# cslr_aif register map
Vendor: Texas Instruments
Peripheral module from a debugger description file.
Registers are 32-bit, access per field, reset 0x0 unless marked. A register's access mark holds for its fields unless they carry their own. Offsets are as the file gives them; lines under a group give offsets from that group; [hi:lo] are bit positions; {n}, {i} and the like mark numbered series; 'fields as' and 'values as' point back to an identical list; <NAME> marks a mode.

## AIF (part 1 of 5) — High-speed interface for BTS antenna data
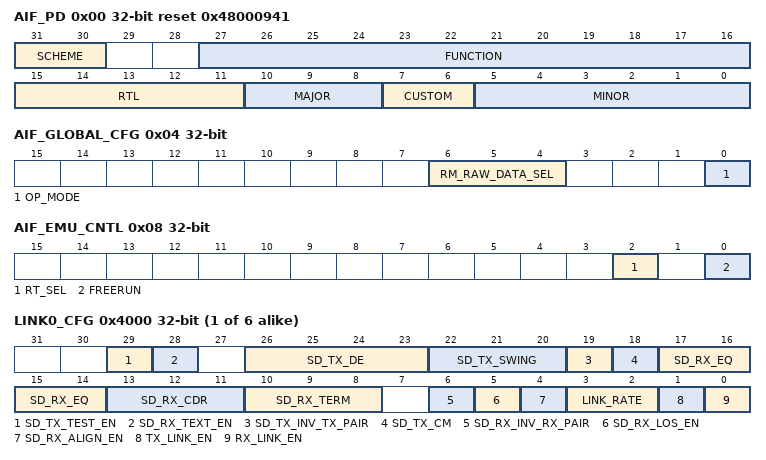
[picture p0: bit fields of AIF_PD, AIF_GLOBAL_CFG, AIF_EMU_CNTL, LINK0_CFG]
0x00 AIF_PD ro reset 0x48000941 — AI Periperal ID
  [31:30] SCHEME — Hard-coded to "01" to indicate current scheme
  [27:16] FUNCTION — Function code assigned to AI. Hard-coded to 0x800
  [15:11] RTL — RTL version code
  [10:8] MAJOR — Major revision (X) code
  [7:6] CUSTOM — Custom version code
  [5:0] MINOR — Minor revision (Y) code
0x04 AIF_GLOBAL_CFG — AI Global Configuration
  [6:4] RM_RAW_DATA_SEL rw — Select 1 of 6 links of raw (not gated) RX MAC output data used for data tracing feature.
  [0] OP_MODE rw — Select OBSAI '0' or CPRI '1' Operating mode. This bit must be set at device configuration and not changed.
0x08 AIF_EMU_CNTL — AI Emulation Control
  [2] RT_SEL rw — Source of emulation suspend signal
    0=EMUSUSP (Halt on emulation suspend); 1=EMUSUSP_RT (Halt on real-time emulation suspend)
  [0] FREERUN rw — Controls whether or not the AIF will respond to the emulation suspend signal, selected by RT_SEL
    0=HALT (AIF responds to emulation suspend signal); 1=FREE (AIF ignores the emulation suspend signal)
{0x4000+0x800*i} LINK{i}_CFG (i=0..5) — Link Configuration Register
  [29] SD_TX_TEST_EN rw — Enables test modes specified via TESTCFG for this transmitter (see SERDES spec)
  [28] SD_RX_TEXT_EN rw — Enables test modes specified via TESTCFG for this receiver (see SERDES spec)
  [26:23] SD_TX_DE rw — Selects one of 15 output de- emphasis settings from 4.76 to 71.42% (see SERDES spec)
  [22:20] SD_TX_SWING rw — Selects one of 8 output amplitude settings between 125 and 1250mVdfpp (see SERDES spec)
  [19] SD_TX_INV_TX_PAIR rw — Inverts polarity of TXPi and TXNi (see SERDES spec)
  [18] SD_TX_CM rw — Adjusts the common mode to suit the termination at the attached receiver (see SERDES spec)
  [17:14] SD_RX_EQ rw — Enables and configures the adaptive equalizer to compensate for loss in the transmission media (see SERDES spec)
  [13:11] SD_RX_CDR rw — Configures the clock/data recovery algorithm (see SERDES spec)
  [10:8] SD_RX_TERM rw — Selects input termination options suitable for variety of AC or DC coupled scenarios (see SERDES spec)
  [6] SD_RX_INV_RX_PAIR rw — Inverts polarity of RXPi and RXNi (see SERDES spec)
  [5] SD_RX_LOS_EN rw — Enable serdes loss of signal:
    0=DISABLED; 1=ENABLED
  [4] SD_RX_ALIGN_EN rw — Enables internal or external symbol alignment.
    0=DISABLED (Comma Alignment disabled); 1=ENABLED (Comma Alignment enabled)
  [3:2] LINK_RATE rw — Select both RX and TX line rate per link:
    0=4X; 1=2X; 2=1X
  [1] TX_LINK_EN rw — TX link enable: Affects SERDES, TX MAC, AG and PE.
    0=DISABLED; 1=ENABLED
  [0] RX_LINK_EN rw — RX link enable. Affects SERDES, RX MAC, CD and PD.
    0=DISABLED; 1=ENABLED
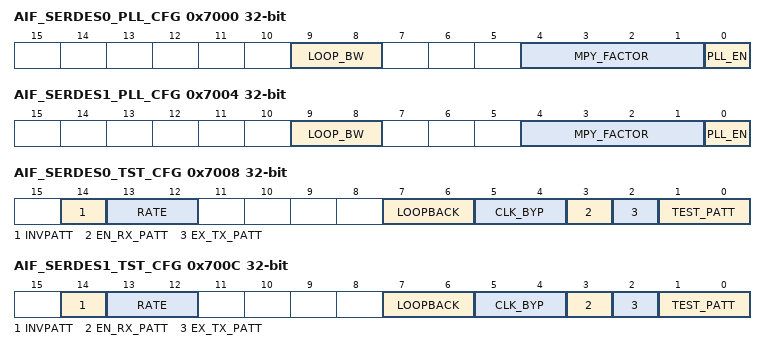
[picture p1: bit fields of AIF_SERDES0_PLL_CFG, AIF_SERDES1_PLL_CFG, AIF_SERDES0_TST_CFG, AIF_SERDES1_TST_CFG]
0x7000 AIF_SERDES0_PLL_CFG — AI Serdes 0 PLL Configuration
  [9:8] LOOP_BW rw — Specify loop bandwidth settings
  [4:1] MPY_FACTOR rw — Select PLL multiply factor (AI supports between 4 and 25)
  [0] PLL_EN rw — Enable PLL
    0=DISABLED; 1=ENABLED
0x7004 AIF_SERDES1_PLL_CFG — AI Serdes 1 PLL Configuration
  fields as AIF_SERDES0_PLL_CFG
0x7008 AIF_SERDES0_TST_CFG — AI Serdes 0 Test Configuration
  [14] INVPATT rw — Inverts polarity of pattern generator.
  [13:12] RATE rw — Selects rate for tx pattern generator.
  [7:6] LOOPBACK rw — Selects internal or bump/pad loopback
  [5:4] CLK_BYP rw — Facilitates bypassing of the PLL clock and bypassing of the recovered receive clock.
  [3] EN_RX_PATT rw — Enables generation of test patterns in the receiver
  [2] EX_TX_PATT rw — Enables generation of test patterns in the transmitter
  [1:0] TEST_PATT rw — Test Pattern selects one of two PRBS or two clock test patterns
0x700C AIF_SERDES1_TST_CFG — AI Serdes 1 Test Configuration
  fields as AIF_SERDES0_TST_CFG
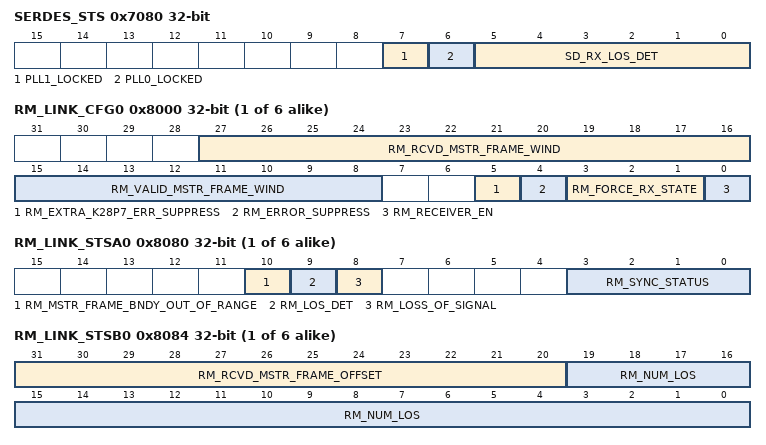
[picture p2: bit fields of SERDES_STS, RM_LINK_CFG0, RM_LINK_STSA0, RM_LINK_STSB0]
0x7080 SERDES_STS ro — SERDES Status Register
  [7] PLL1_LOCKED — Driven high when the PLL 1 is locked.
  [6] PLL0_LOCKED — Driven high when the PLL 0 is locked.
  [5:0] SD_RX_LOS_DET — Driven high when a loss of signal (electrical idle) condition is detected per link.
{0x8000+0x800*i} RM_LINK_CFG{i} (i=0..5) — Rx MAC Link Configuration Register
  [27:16] RM_RCVD_MSTR_FRAME_WIND rw — Defines the measurement window for received Master Frame Offset, given in the number of vbus_clk tics.
    0=DISABLE
  [15:8] RM_VALID_MSTR_FRAME_WIND rw — Defines the measurement window for valid Master Frame Offset, given in the number of vbus_clk tics. Related to the error: mstr_frame_bndry_out_of_range.
    0=DISABLE
  [5] RM_EXTRA_K28P7_ERR_SUPPRESS rw — Suppress error reporting of "extra" K28.7 characters detected in the data stream. RP3 requires that "messages be rejected when Master Frame boundary is detected outside the allowed window".
    0=ALLOW (Allow error reporting of extra K28.7 characters); 1=SUPPRESS (Suppress error reporting of extra K28.7 characters)
  [4] RM_ERROR_SUPPRESS rw — Suppress error reporting when the receiver state machine is not in state ST3.
    0=ALLOW (Allow RM error reporting when !ST3); 1=SUPPRESS (Suppress RM error reporting when !ST3)
  [3:1] RM_FORCE_RX_STATE rw — Force receiver state machine state: 0xx - not active, 100 - force ST0 state, 101 - force ST1 state, 110 - force ST2, 111 - force ST3 state.
  [0] RM_RECEIVER_EN rw — Enable '1' or disable '0' RX MAC.
    0=DISABLED; 1=ENABLED
{0x8004+0x800*i} RM_LINK_PI_OFFSET_CFG{i} (i=0..5) — Rx MAC Link Pi Offset Configuration Register
  [19:0] RM_PI_OFFSET rw — A 2's compliment number specifying the delay from Frame Sync to the expected Master Frame / Hyper Frame boundary (OBSAI RP3: K28.7 or CPRI: K28.5 AND HFN = 149) within ~65 ns (about 5, 1x link byte clocks) and given in the number of vbus_clk tics.
{0x8008+0x800*i} RM_LINK_LOS_THOLD_CFG{i} (i=0..5) — Rx MAC Link LoS Threshold Configuration Register
  [19:0] RM_LOS_DET_THOLD rw — Sets 8b10b los detect threshold values in number of Line Code Violations received. Writing to this location will automatically clear the rm_num_los counter and rm_los_det status bit.
{0x8080+0x800*i} RM_LINK_STSA{i} ro (i=0..5) — RX MAC Link Status Register A
  [10] RM_MSTR_FRAME_BNDY_OUT_OF_RANGE — This error is indicated when received Master Frame is detected outside the programmable window valid_mstr_frame_wind. This error will not be reported if an "extra" K28.7 character is detected AND rm_extra_k28p7_err_suppress = 1.
  [9] RM_LOS_DET — Detectes when rm_num_los counter has reached the programmable rm_los_det_thold limit.
    0=NOT_DETECTED; 1=DETECTED
  [8] RM_LOSS_OF_SIGNAL — Active when rx state machine is in ST0 state, inactive otherwise.
  [3:0] RM_SYNC_STATUS — Indicates the current status of the rx state machine. ST0 = '1000', ST1 = '0100', ST2 = '0010', ST3 = '0001'
{0x8084+0x800*i} RM_LINK_STSB{i} ro (i=0..5) — RX MAC Link Status Register B
  [31:20] RM_RCVD_MSTR_FRAME_OFFSET — Reperesents the time in vbus_clk tics from after pi_offset that the frame boundary was received. This value will saturate at either the programmed rm_rcvd_mstr_frame_wind threshold or the max value of 4095. This measurement is conducted once per frame.
  [19:0] RM_NUM_LOS — This error is indicated when received Master Frame is detected outside the programmable window valid_mstr_frame_wind. This error will not be reported if an "extra" K28.7 character is detected AND rm_extra_k28p7_err_suppress = 1.
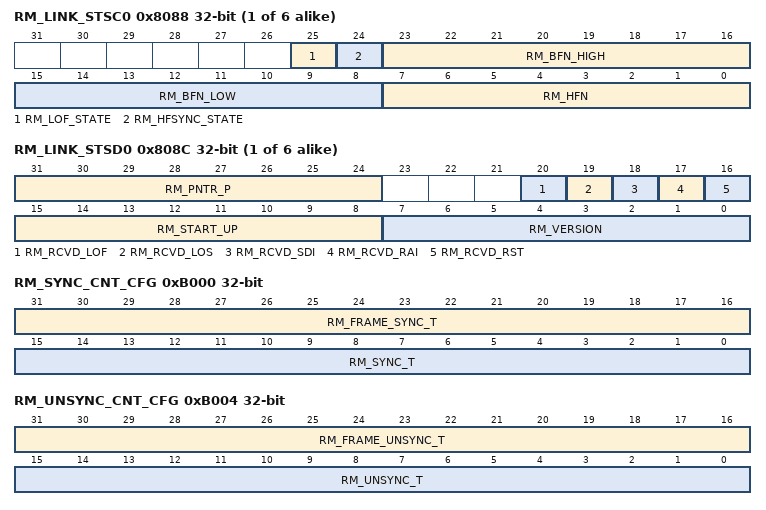
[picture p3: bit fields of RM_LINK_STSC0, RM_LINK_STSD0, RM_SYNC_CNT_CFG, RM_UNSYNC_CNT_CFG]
{0x8088+0x800*i} RM_LINK_STSC{i} (i=0..5) — RX MAC Link Status Register C
  [25] RM_LOF_STATE rw — Active high status indicates Loss Of Frame when the receiver FSM is in state ST0 or ST1.
  [24] RM_HFSYNC_STATE rw — Active high status indicates when the receiver FSM is in the HFSYNC state ST3.
  [23:16] RM_BFN_HIGH ro — Received Node B Frame number high byte (Z.130.0)
  [15:8] RM_BFN_LOW ro — Received Node B Frame number low byte (Z.128.0)
  [7:0] RM_HFN ro — Received Hyperframe number (Z.64.0)
{0x808C+0x800*i} RM_LINK_STSD{i} ro (i=0..5) — RX MAC Link Status Register D
  [31:24] RM_PNTR_P — Received Pointer P
  [20] RM_RCVD_LOF — Received lof (Z.130.0, b4)
  [19] RM_RCVD_LOS — Received los (Z.130.0, b3)
  [18] RM_RCVD_SDI — Received sdi (Z.130.0, b2)
  [17] RM_RCVD_RAI — Received rai (Z.130.0, b1)
  [16] RM_RCVD_RST — Received reset (Z.130.0, b0)
  [15:8] RM_START_UP — Received start-up information (Z.66.0)
  [7:0] RM_VERSION — Received protocol version (Z.2.0)
0xB000 RM_SYNC_CNT_CFG rw — Rx MAC Sync Count Configuration Register
  [31:16] RM_FRAME_SYNC_T — Threshold value for consecutive valid message groups which result in state ST3
  [15:0] RM_SYNC_T — Threshold value for consecutive valid blocks of bytes which result in state ST1.
0xB004 RM_UNSYNC_CNT_CFG rw — Rx MAC Unsync Count Configuration Register
  [31:16] RM_FRAME_UNSYNC_T — Threshold value for consecutive invalid message groups which result in state ST1.
  [15:0] RM_UNSYNC_T — Threshold value for consecutive invalid blocks of bytes which result in state ST0.
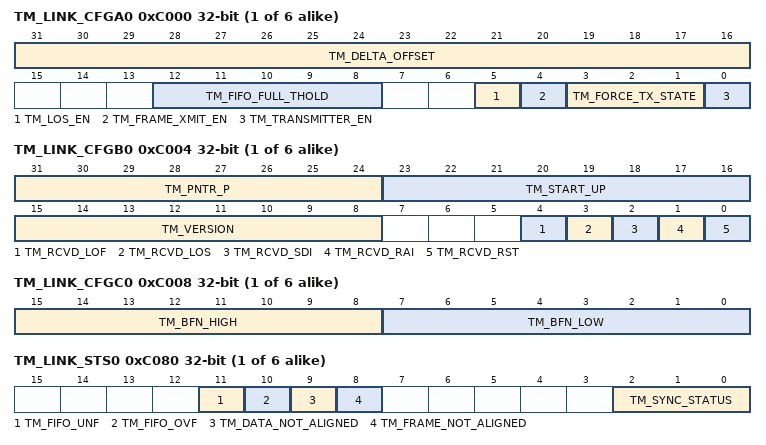
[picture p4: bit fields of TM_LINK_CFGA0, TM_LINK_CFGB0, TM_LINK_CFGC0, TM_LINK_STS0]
{0xC000+0x800*i} TM_LINK_CFGA{i} (i=0..5) — Tx MAC Link Configuration RegisterA
  [31:16] TM_DELTA_OFFSET rw — A 2's compliment number specifying the delay from Frame Sync to start of Master Frame in 1x link byte-clock ticks (13ns) increments.
  [12:8] TM_FIFO_FULL_THOLD rw — Sets the threshold for the full indication flag for the TX MAC FIFO.
  [5] TM_LOS_EN rw — Enable impact of the rm_loss_of_signal to the transmitter state machine:
    0=DISABLED; 1=ENABLED
  [4] TM_FRAME_XMIT_EN rw — Enable allowing the TX FSM from entering state ST2. Thisbit will have no effect if the state machine is already in state ST2.
    0=DISABLED; 1=ENABLED
  [3:1] TM_FORCE_TX_STATE rw — Force transmitter state machine state:
    0=NOT_ACTIVE0; 4=FORCE_ST0; 5=FORCE_ST1; 6=FORCE_ST2
  [0] TM_TRANSMITTER_EN rw — TX MAC enable:
    0=DISABLED; 1=ENABLED
{0xC004+0x800*i} TM_LINK_CFGB{i} rw (i=0..5) — Tx MAC Link Configuration Register B
  [31:24] TM_PNTR_P — Transmit Pointer P
  [23:16] TM_START_UP — Transmit start-up information (Z.66.0)
  [15:8] TM_VERSION — Transmit protocol version (Z.2.0)
  [4] TM_RCVD_LOF — Transmit lof (Z.130.0, b4)
  [3] TM_RCVD_LOS — Transmit los (Z.130.0, b3)
  [2] TM_RCVD_SDI — Transmit sdi (Z.130.0, b2)
  [1] TM_RCVD_RAI — Transmit rai (Z.130.0, b1)
  [0] TM_RCVD_RST — Transmit reset (Z.130.0, b0)
{0xC008+0x800*i} TM_LINK_CFGC{i} (i=0..5) — Tx MAC Link Configuration Register C
  [15:8] TM_BFN_HIGH rw — Transmit Node B Frame number high byte (Z.130.0) - loads u_cntr high byte
  [7:0] TM_BFN_LOW rw — Transmit Node B Frame number low byte (Z.128.0) - loads u_cntr low byte
{0xC080+0x800*i} TM_LINK_STS{i} ro (i=0..5) — TX MAC Link Status Register
  [11] TM_FIFO_UNF — TX MAC FIFO Underflow flag
  [10] TM_FIFO_OVF — TX MAC FIFO Overflow flag
  [9] TM_DATA_NOT_ALIGNED — This error is indicated when data to be transmitted is detected as not aligned with Master Frame + delta_offset (i.e. Frame boundary to be transmitted is not aligned with frame boundary received internally)
  [8] TM_FRAME_NOT_ALIGNED — This error is indicated when the frame strobe from the Frame Sync Module is not aligned with Master Frame + delta_offset.
  [2:0] TM_SYNC_STATUS — Indicates the current status of the tx state machine.
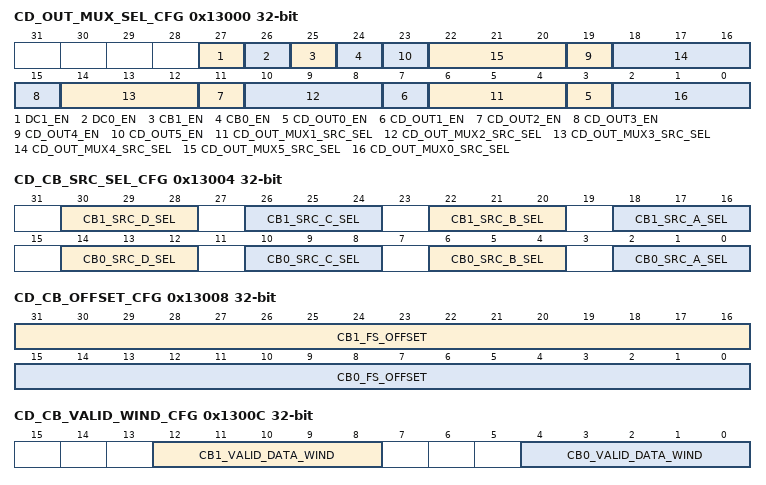
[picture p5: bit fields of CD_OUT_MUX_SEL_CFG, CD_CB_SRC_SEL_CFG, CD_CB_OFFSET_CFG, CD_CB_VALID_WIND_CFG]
0x13000 CD_OUT_MUX_SEL_CFG — Combiner - Decombiner Output Mux Select Config Register 0
  [27] DC1_EN rw — Decombiner 1 enable
    0=DISABLE; 1=ENABLE
  [26] DC0_EN rw — Decombiner 0 enable
    0=DISABLE; 1=ENABLE
  [25] CB1_EN rw — Combiner 1 enable
    0=DISABLE; 1=ENABLE
  [24] CB0_EN rw — Combiner 0 enable
    0=DISABLE; 1=ENABLE
  [4n+3] CD_OUT{n}_EN rw (n=0..5) — CD output {n} enable: Disable = 0, Enable =1 output link {n} of the Combiner / Decombiner.
    0=DISABLE; 1=ENABLE
  [4n+2:4n] CD_OUT_MUX{n}_SRC_SEL rw (n=1..5) — Select source of link {n} output
    {v}=LINK_{v} (v=0..5); 6=CB_0; 7=CB_1
  [2:0] CD_OUT_MUX0_SRC_SEL rw — Select source of link 0 output:
    {v}=LINK_{v} (v=0..5); 6=CB_0; 7=CB_1
0x13004 CD_CB_SRC_SEL_CFG — Combiner Source Select Config Register
  [all] fields
    {v}=LINK_{v} (v=0..5)
  [30:28] CB1_SRC_D_SEL rw — Combiner 1 input source link select table entry 'd'
  [26:24] CB1_SRC_C_SEL rw — Combiner 1 input source link select table entry 'c'
  [22:20] CB1_SRC_B_SEL rw — Combiner 1 input source link select table entry 'b'
  [18:16] CB1_SRC_A_SEL rw — Combiner 1 input source link select table entry 'a'
  [14:12] CB0_SRC_D_SEL rw — Combiner 0 input source link select table entry 'd'
  [10:8] CB0_SRC_C_SEL rw — Combiner 0 input source link select table entry 'c'
  [6:4] CB0_SRC_B_SEL rw — Combiner 0 input source link select table entry 'b'
  [2:0] CB0_SRC_A_SEL rw — Combiner 0 input source link select table entry 'a'
0x13008 CD_CB_OFFSET_CFG rw — Combiner Alignment Offset Config Register
  [31:16] CB1_FS_OFFSET — Combiner 1 offset from frame sync. Similar to RX MAC pi_offset. This value is used to check input link frame alignment.
  [15:0] CB0_FS_OFFSET — Combiner 0 offset from frame sync. Similar to RX MAC pi_offset. This value is used to check input link frame alignment.
0x1300C CD_CB_VALID_WIND_CFG — Combiner Valid Window Config Register
  [12:8] CB1_VALID_DATA_WIND rw — Combiner 1 valid data window for Master Frame Offset in vbus clock ticks
  [4:0] CB0_VALID_DATA_WIND rw — Combiner 0 valid data window for Master Frame Offset in vbus clock ticks
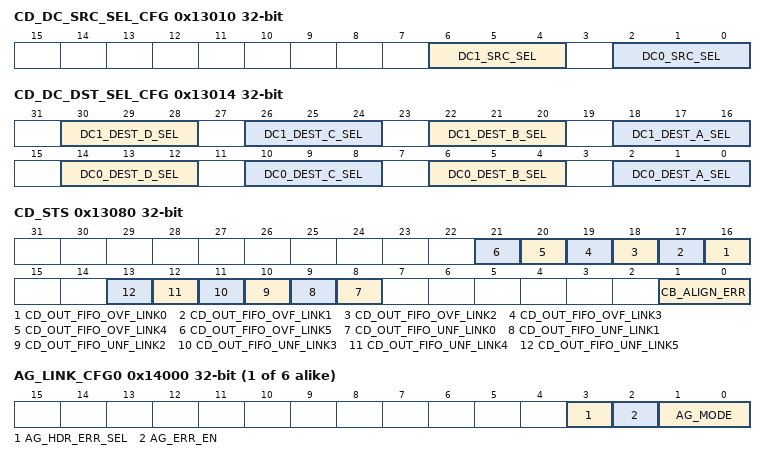
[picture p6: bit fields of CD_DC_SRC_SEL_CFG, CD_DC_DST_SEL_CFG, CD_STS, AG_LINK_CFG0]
0x13010 CD_DC_SRC_SEL_CFG — Decombiner Source Select Config Register
  [6:4] DC1_SRC_SEL rw — Decombiner 1 source
    {v}=LINK_{v} (v=0..5)
  [2:0] DC0_SRC_SEL rw — Decombiner 0 source
    {v}=LINK_{v} (v=0..5)
0x13014 CD_DC_DST_SEL_CFG — Decombiner Destination Select Config Register
  [all] fields
    {v}=LINK_{v} (v=0..5)
  [30:28] DC1_DEST_D_SEL rw — Decombiner 1 output destination link select table entry 'd'
  [26:24] DC1_DEST_C_SEL rw — Decombiner 1 output destination link select table entry 'c'
  [22:20] DC1_DEST_B_SEL rw — Decombiner 1 output destination link select table entry 'b'
  [18:16] DC1_DEST_A_SEL rw — Decombiner 1 output destination link select table entry 'a'
  [14:12] DC0_DEST_D_SEL rw — Decombiner 0 output destination link select table entry 'd'
  [10:8] DC0_DEST_C_SEL rw — Decombiner 0 output destination link select table entry 'c'
  [6:4] DC0_DEST_B_SEL rw — Decombiner 0 output destination link select table entry 'b'
  [2:0] DC0_DEST_A_SEL rw — Decombiner 0 output destination link select table entry 'a'
0x13080 CD_STS ro — Combiner - Decombiner Status Register
  [n+16] CD_OUT_FIFO_OVF_LINK{n} (n=0..5) — Active high. CD output FIFO overflow flag per link
  [n+8] CD_OUT_FIFO_UNF_LINK{n} (n=0..5) — Active high. CD output FIFO underflow flag per link
  [1:0] CB_ALIGN_ERR — Active high. Indicates frame alignment error for each of the two combiners.
{0x14000+0x800*i} AG_LINK_CFG{i} (i=0..5) — Aggregator Link Configuration Register
  [3] AG_HDR_ERR_SEL rw — Controls the data source selected by aggregator when there is an OBSAI header mismatch and the PE is requesting aggregation
  [2] AG_ERR_EN rw — Aggregator error checking enable: 0 = aggregator error checking disabled, 1 = aggregator error checking enabled.
  [1:0] AG_MODE rw — Select aggregator mode: 00 = Not enabled (no data sent to the TX MAC), 01 = Pass thru from Combiner only, 10 = Insertion from the Protocol Encoder only, 11 = All aggregation functions enabled.
{0x14004+0x800*i} AG_LINK_STS{i} ro (i=0..5) — Aggregator Link Error Status Register
  [15:0] AG_AXC_SUM_OVF — Summation overflow per AxC.
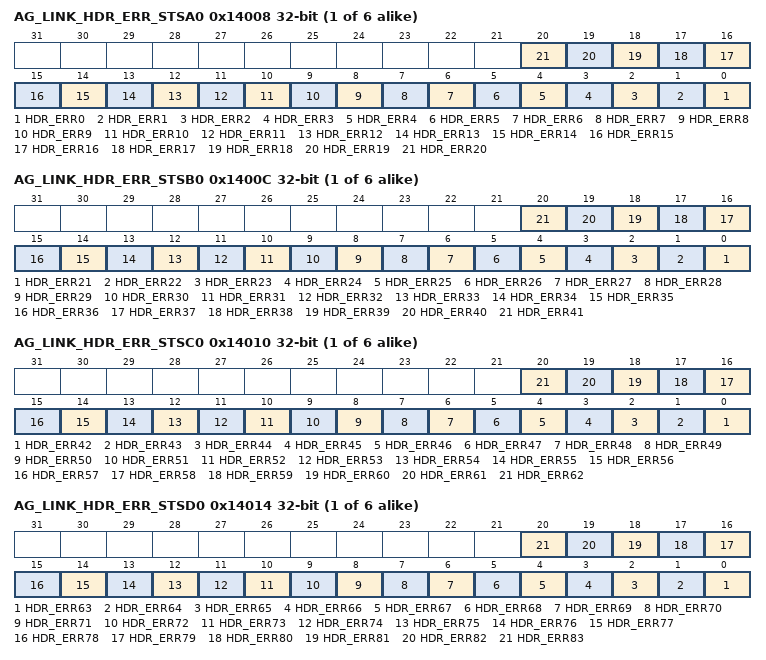
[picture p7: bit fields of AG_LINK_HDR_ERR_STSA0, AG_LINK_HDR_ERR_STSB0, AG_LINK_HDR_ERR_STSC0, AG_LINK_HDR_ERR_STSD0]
{0x14008+0x800*i} AG_LINK_HDR_ERR_STSA{i} ro (i=0..5) — Aggregator Link Header Error Status Register A
  [all] fields
    0=NO_ERR; 1=ERR
  [n] HDR_ERR{n} (n=0..20) — Aggregator header error for slot {n}
{0x1400C+0x800*i} AG_LINK_HDR_ERR_STSB{i} ro (i=0..5) — Aggregator Link Header Error Status Register B
  [all] fields
    0=NO_ERR; 1=ERR
  [n-21] HDR_ERR{n} (n=21..41) — Aggregator header error for slot {n}
{0x14010+0x800*i} AG_LINK_HDR_ERR_STSC{i} ro (i=0..5) — Aggregator Link Header Error Status Register C
  [all] fields
    0=NO_ERR; 1=ERR
  [n-42] HDR_ERR{n} (n=42..62) — Aggregator header error for slot {n}
{0x14014+0x800*i} AG_LINK_HDR_ERR_STSD{i} ro (i=0..5) — Aggregator Link Header Error Status Register D
  [all] fields
    0=NO_ERR; 1=ERR
  [n-63] HDR_ERR{n} (n=63..83) — Aggregator header error for slot {n}
{0x18000+0x800*i} CI_LINK_CFG{i} (i=0..5) — CPRI Link Input Data Format Converter Configuration Registers
  [1:0] CI_DATA_FMT rw — CPRI data format:
    0=UL_PIC_7BIT; 1=UL_PIC_8BIT; 2=DL_GEN_15BIT; 3=DL_GEN_16BIT
{0x1C000+0x800*i} CO_LINK_CFG{i} (i=0..5) — CPRI Link Output Data Format Converter Configuration Registers
  [1:0] CO_DATA_FMT rw — CPRI data format:
    0=UL_PIC_7BIT; 1=UL_PIC_8BIT; 2=DL_GEN_15BIT; 3=DL_GEN_16BIT
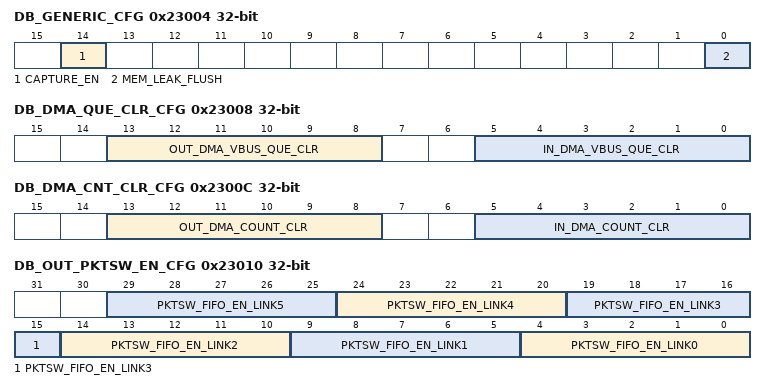
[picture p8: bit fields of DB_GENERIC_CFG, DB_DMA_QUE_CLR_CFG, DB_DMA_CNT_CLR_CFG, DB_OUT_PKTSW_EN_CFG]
0x23004 DB_GENERIC_CFG — Data Buffer Configuration Register
  [14] CAPTURE_EN rw — Enables "Logic Analyzer" capture
  [0] MEM_LEAK_FLUSH rw — Flushes all outbound pktsw fifo's if a memory leak is detected
0x23008 DB_DMA_QUE_CLR_CFG — Data Buffer DMA Depth Clear Register
  [13:8] OUT_DMA_VBUS_QUE_CLR wo — Bits [5:0]: Bit mapped per link, clears the Outbound DMA VBUS Queue counters
  [5:0] IN_DMA_VBUS_QUE_CLR wo — Bits [5:0]: Bit mapped per link, clears the Inbound DMA VBUS Queue counters
0x2300C DB_DMA_CNT_CLR_CFG — Data Buffer DMA Count Clear Register
  [13:8] OUT_DMA_COUNT_CLR wo — Bits [5:0]: Bit mapped per link, clears the Outbound DMA "Depth" counters
  [5:0] IN_DMA_COUNT_CLR wo — Bits [5:0]: Bit mapped per link, clears the Inbound DMA "Depth" counters
0x23010 DB_OUT_PKTSW_EN_CFG — Data Buffer Outbound Packet Switched FIFO Enable Register
  [5n+4:5n] PKTSW_FIFO_EN_LINK{n} rw (n=0..5) — Bit mapped per Channel, Enables Packet Switched Outbound FIFOs
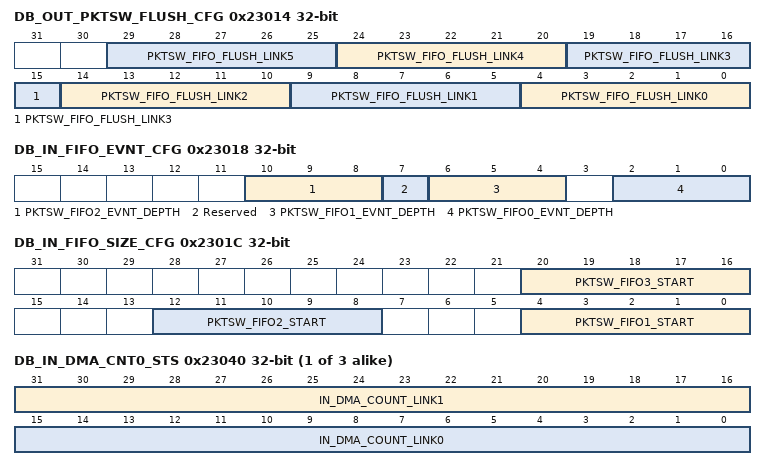
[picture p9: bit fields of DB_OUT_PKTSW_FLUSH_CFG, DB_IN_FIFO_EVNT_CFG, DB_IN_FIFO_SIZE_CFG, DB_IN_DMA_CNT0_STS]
0x23014 DB_OUT_PKTSW_FLUSH_CFG — Data Buffer Inbound Packet Switched FIFO Flush Register
  [5n+4:5n] PKTSW_FIFO_FLUSH_LINK{n} wo (n=0..5) — Bit mapped per Channel, Enables Packet Switched Outbound FIFOs
0x23018 DB_IN_FIFO_EVNT_CFG access not given — Data Buffer Inbound Packet Switched FIFO Flush Register
  [10:8] PKTSW_FIFO2_EVNT_DEPTH rw — Inbound Packet Swtiched FIFO #2, programmable depth of system event
    0=DEPTH_01 (Queue depth of 1); 1=DEPTH_02 (Queue depth of 2); 2=DEPTH_04 (Queue depth of 4); 3=DEPTH_08 (Queue depth of 8); 4=DEPTH_16 (Queue depth of 16); 5=DEPTH_32 (Queue depth of 32)
  [7] Reserved — (access N)
  [6:4] PKTSW_FIFO1_EVNT_DEPTH rw — Inbound Packet Swtiched FIFO #1, programmable depth of system event
    values as PKTSW_FIFO2_EVNT_DEPTH
  [2:0] PKTSW_FIFO0_EVNT_DEPTH rw — Inbound Packet Swtiched FIFO #0, programmable depth of system event
    values as PKTSW_FIFO2_EVNT_DEPTH
0x2301C DB_IN_FIFO_SIZE_CFG — Data Buffer Inbound Packet Switched FIFO Depth Register
  [20:16] PKTSW_FIFO3_START rw — Inbound Packet Swtiched FIFO #3 start
  [12:8] PKTSW_FIFO2_START rw — Inbound Packet Swtiched FIFO #2 start
  [4:0] PKTSW_FIFO1_START rw — Inbound Packet Swtiched FIFO #1 start
{0x23040+4i} DB_IN_DMA_CNT{i}_STS ro (i=0..2) — Data Buffer Inbound DMA Count {i} Register
  [31:16] IN_DMA_COUNT_LINK{2i+1} — DMA Inbound Done Register Occurances for Link {2i+1}
  [15:0] IN_DMA_COUNT_LINK{2i} — DMA Inbound Done Register Occurances for Link {2i}
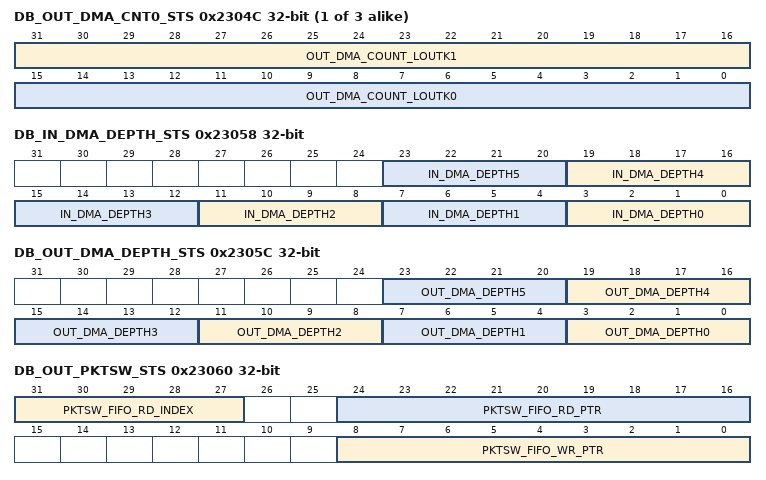
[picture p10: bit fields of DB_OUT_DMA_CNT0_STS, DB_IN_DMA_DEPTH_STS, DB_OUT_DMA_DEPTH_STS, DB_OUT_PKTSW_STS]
{0x2304C+4i} DB_OUT_DMA_CNT{i}_STS ro (i=0..2) — Data Buffer Outbound DMA Count {i} Register
  [31:16] OUT_DMA_COUNT_LOUTK{2i+1} — DMA Outbound Done Register Occurances for Link {2i+1}
  [15:0] OUT_DMA_COUNT_LOUTK{2i} — DMA Outbound Done Register Occurances for Link {2i}
0x23058 DB_IN_DMA_DEPTH_STS — Data Buffer Inbound DMA Burst Available Register
  [4n+3:4n] IN_DMA_DEPTH{n} rw (n=0..5) — Number of DMA bursts written into DB by PD for Link {n}
0x2305C DB_OUT_DMA_DEPTH_STS — Data Buffer Outbound DMA Burst Available Register
  [4n+3:4n] OUT_DMA_DEPTH{n} rw (n=0..5) — Number of DMA bursts written into DB by PE for Link {n}
0x23060 DB_OUT_PKTSW_STS ro — Data Buffer Outbound Packet Switched FIFO status Register
  [31:27] PKTSW_FIFO_RD_INDEX — Fifo Index 0-to-29 indicating which of 30 FIFOs has the lowest, non-read memory location.
  [24:16] PKTSW_FIFO_RD_PTR — Current state of the "lowest" Read/head pointer, Represents "lowest" non-read memory location of all 30 FIFO's.
  [8:0] PKTSW_FIFO_WR_PTR — Oubtound Packet Switched Memory, Current state of the circular write pointer
0x23064 DB_OUT_PKTSW_DEPTH_STS ro — Data Buffer Outbound Packet Switched FIFO Depth Register
  [8:0] PKT_SW_FIFO_DEPTH — Indicates depth of Packet Switched FIFO currently available for writes.
0x23068 DB_OUT_PKTSW_NE_STS ro — Data Buffer Outbound Packet Switched FIFO Not Empty Register
  [29:0] PKT_SW_FIFO_NE — Outbound packet switched FIFO 0-29 indicates FIFO not empty
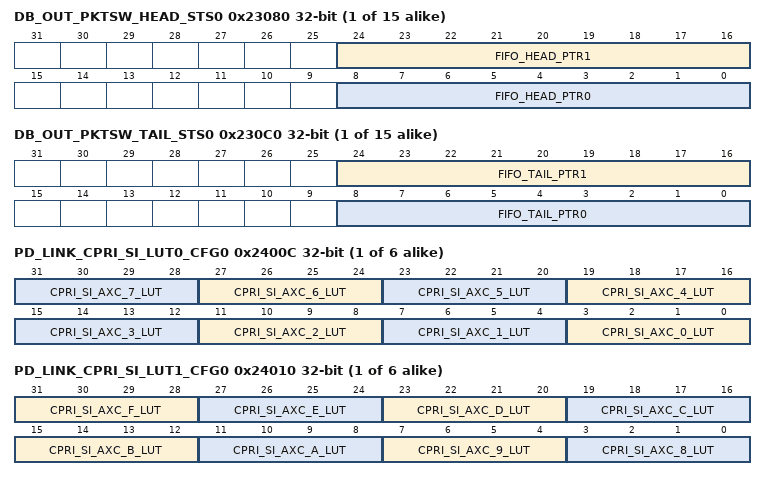
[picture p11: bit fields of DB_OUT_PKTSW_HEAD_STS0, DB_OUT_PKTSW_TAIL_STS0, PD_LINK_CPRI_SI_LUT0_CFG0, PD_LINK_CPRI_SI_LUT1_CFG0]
{0x23080+4i} DB_OUT_PKTSW_HEAD_STS{i} ro (i=0..14) — Data Buffer Outbound Packet Switched FIFO Head Pointer
  [24:16] FIFO_HEAD_PTR1 — Packet Swtiched FIFO #1, Current state of head pointer for FIFO {1, 3, 5, 7, 29}
  [8:0] FIFO_HEAD_PTR0 — Packet Swtiched FIFO #0, Current state of head pointer for FIFO {0, 2, 4, 6, 28}
{0x230C0+4i} DB_OUT_PKTSW_TAIL_STS{i} ro (i=0..14) — Data Buffer Outbound Packet Switched FIFO Tail Pointer
  [24:16] FIFO_TAIL_PTR1 — Packet Swtiched FIFO #1, Current state of tail pointer for FIFO {1, 3, 5, 7, 29}
  [8:0] FIFO_TAIL_PTR0 — Packet Swtiched FIFO #0, Current state of tail pointer for FIFO {0, 2, 4, 6, 28}
{0x24000+0x800*i} PD_LINK_84CNT_LUT0_CFG{i} rw (i=0..5) — Protocol Decoder 84 Count LUT0 Link Configuration Register
  [31:0] TIME_STAMP_INCR_NXT_LUT0 — Bits [31:0], Bit mapped by 84 count. Controls Time Stamp to increment, Incremented value is used for next message. (Only used for OBSAI, CPRI TS increments every basic frame)
{0x24004+0x800*i} PD_LINK_84CNT_LUT1_CFG{i} rw (i=0..5) — Protocol Decoder 84 Count LUT1 Link Configuration Register
  [31:0] TIME_STAMP_INCR_NXT_LUT1 — Bits [63:32], Bit mapped by 84 count. Controls Time Stamp to increment, Incremented value is used for current operation
{0x24008+0x800*i} PD_LINK_84CNT_LUT2_CFG{i} rw (i=0..5) — Protocol Decoder 84 Count LUT2 Link Configuration Register
  [31:0] TIME_STAMP_INCR_NXT_LUT2 — Bits [83:64], Bit mapped by 84 count. Controls Time Stamp to increment, Incremented value is used for current operation
{0x2400C+0x800*i} PD_LINK_CPRI_SI_LUT0_CFG{i} rw (i=0..5) — Protocol Decoder CPRI Stream Index LUT0 Register
  [4n+3:4n] CPRI_SI_AXC_{n}_LUT (n=0..7) — AxC{n}, CPRI stream index (SI). 0-to-15 value corresponding to streams organized in circuit switched RAM. Used for address generation. AxC value used to index LUT. (In OBSAI mode, address_lut serves this purpose)
{0x24010+0x800*i} PD_LINK_CPRI_SI_LUT1_CFG{i} rw (i=0..5) — Protocol Decoder CPRI Stream Index LUT1 Register
  [31:28] CPRI_SI_AXC_F_LUT — AxCf, CPRI stream index (SI). 0-to-15 value corresponding to streams organized in circuit switched RAM. Used for address generation. AxC value used to index LUT. (In OBSAI mode, address_lut serves this purpose)
  [27:24] CPRI_SI_AXC_E_LUT — AxCe, CPRI stream index (SI). 0-to-15 value corresponding to streams organized in circuit switched RAM. Used for address generation. AxC value used to index LUT. (In OBSAI mode, address_lut serves this purpose)
  [23:20] CPRI_SI_AXC_D_LUT — AxCd, CPRI stream index (SI). 0-to-15 value corresponding to streams organized in circuit switched RAM. Used for address generation. AxC value used to index LUT. (In OBSAI mode, address_lut serves this purpose)
  [19:16] CPRI_SI_AXC_C_LUT — AxCc, CPRI stream index (SI). 0-to-15 value corresponding to streams organized in circuit switched RAM. Used for address generation. AxC value used to index LUT. (In OBSAI mode, address_lut serves this purpose)
  [15:12] CPRI_SI_AXC_B_LUT — AxCb, CPRI stream index (SI). 0-to-15 value corresponding to streams organized in circuit switched RAM. Used for address generation. AxC value used to index LUT. (In OBSAI mode, address_lut serves this purpose)
  [11:8] CPRI_SI_AXC_A_LUT — AxCa, CPRI stream index (SI). 0-to-15 value corresponding to streams organized in circuit switched RAM. Used for address generation. AxC value used to index LUT. (In OBSAI mode, address_lut serves this purpose)
  [7:4] CPRI_SI_AXC_9_LUT — AxC9, CPRI stream index (SI). 0-to-15 value corresponding to streams organized in circuit switched RAM. Used for address generation. AxC value used to index LUT. (In OBSAI mode, address_lut serves this purpose)
  [3:0] CPRI_SI_AXC_8_LUT — AxC8, CPRI stream index (SI). 0-to-15 value corresponding to streams organized in circuit switched RAM. Used for address generation. AxC value used to index LUT. (In OBSAI mode, address_lut serves this purpose)
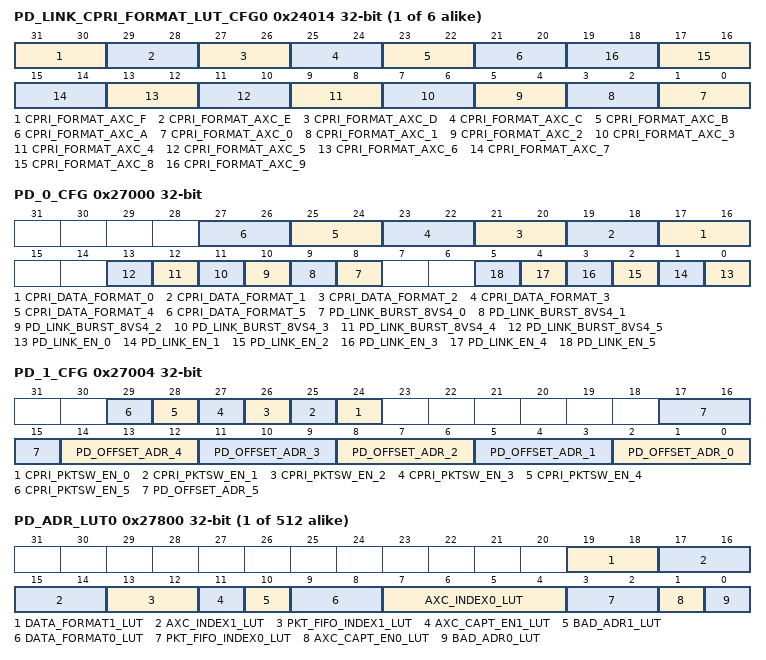
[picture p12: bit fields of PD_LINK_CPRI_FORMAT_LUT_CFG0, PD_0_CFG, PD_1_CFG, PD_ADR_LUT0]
{0x24014+0x800*i} PD_LINK_CPRI_FORMAT_LUT_CFG{i} rw (i=0..5) — Protocol Decoder CPRI Data Format LUT Register
  [31:30] CPRI_FORMAT_AXC_F — AxC F, CPRI Internal Data format:
  [29:28] CPRI_FORMAT_AXC_E — AxC E, CPRI Internal Data format:
  [27:26] CPRI_FORMAT_AXC_D — AxC D, CPRI Internal Data format:
  [25:24] CPRI_FORMAT_AXC_C — AxC C, CPRI Internal Data format:
  [23:22] CPRI_FORMAT_AXC_B — AxC B, CPRI Internal Data format:
  [21:20] CPRI_FORMAT_AXC_A — AxC A, CPRI Internal Data format:
  [2n+1:2n] CPRI_FORMAT_AXC_{n} (n=0..9) — AxC {n}, CPRI Internal Data format:
0x27000 PD_0_CFG — Protocol Decoder Configuration Register 0
  [2n+17:2n+16] CPRI_DATA_FORMAT_{n} rw (n=0..5) — Bit Mapped 2 bits per link, CPRI Internal Data format:
    0=DL; 1=UL; 2=PIC; 3=GENERIC
  [n+8] PD_LINK_BURST_8VS4_{n} rw (n=0..5) — Bits [5:0]: Bit mapped per link
    0=DL; 1=UL
  [n] PD_LINK_EN_{n} rw (n=0..5) — Bits [5:0]: Bit mapped per link
    0=DISABLED; 1=ENABLED
0x27004 PD_1_CFG — Protocol Decoder Configuration Register 1
  [n+24] CPRI_PKTSW_EN_{n} rw (n=0..5) — Bits [5:0]: Bit mapped per link. Enables CPRI control word capture (using pktsw RAM)
    0=DISABLED; 1=ENABLED
  [3n+2:3n] PD_OFFSET_ADR_{n} rw (n=0..5) — Bits [17:0]: Bit mapped 3 bits per link. Circularly offsets writes to circuit switched RAM by n*4 chips. 8 chip orientated UL data disregard the LSB assuming it is zero. This offset is used to correct RAM alignment between streams different MOD32 offsets with one another. Allows chained DMA's to be more regular.
0x27008 PD_ADR_MUX_SEL_CFG — Protocol Decoder OBSAI Adr Mux Select Register
  [19:0] pd_adr_mux_ctrl rw — Bits [19:0]: Bit mapped 2 bits per supported address bit. Used to select which of 13 address bits to use for address LUT index.
0x2700C PD_TYPE_CIR_LUT_CFG rw — Protocol Decoder Type CirSw Capture Enable LUT Register
  [31:0] PD_TYPE_LUT_CIR_SW — Bit mapped per 0-to-31 OBASI type: Enable Circuit Switched, capture to circuit switched RAM
0x27010 PD_TYPE_PKT_LUT_CFG rw — Protocol Decoder Type PktSw Capture Enable LUT Register
  [31:0] PD_TYPE_LUT_PKT_SW — Bit mapped per 0-to-31 OBASI type: Enable Circuit Switched, capture to circuit switched RAM
0x27014 PD_TYPE_ERR_LUT_CFG rw — Protocol Decoder Type Error Register
  [31:0] PD_TYPE_LUT_ERR — Bit mapped per 0-to-31 OBASI type: 1: Illegal OBSAI Type, any Inbound messages with this "type" cause an Error/Alarm condition and trigger Error FIFO capture of message.
{0x27800+4i} PD_ADR_LUT{i} (i=0..511) — Protocol Decoder Address Look Up Table Register
  [19:18] DATA_FORMAT1_LUT rw — odd Addresses: Bits [1:0]: Internal Data format:
  [17:14] AXC_INDEX1_LUT rw — odd Addresses: Bits [3:0]: antenna carrier index, 0-15 used for address generation for circuit switched types (unused for packet switched types)
  [13:12] PKT_FIFO_INDEX1_LUT rw — odd Addresses: Bits [1:0]: Fifo index (used for packet switched type), 0-3 used to direct message to one of four FIFOs.
    0=PS_FIFO0; 1=PS_FIFO1; 2=PS_FIFO2; 3=ERR_FIFO
  [11] AXC_CAPT_EN1_LUT rw — odd Addresses: 1'b1 causes circuit switched type to also capture to Error FIFO (fifo index 0x3)
  [10] BAD_ADR1_LUT rw — odd Addresses: Illegal Address 1'b1: address is indicated to be illegal. Error condition is triggered.
  [9:8] DATA_FORMAT0_LUT rw — Even Addresses: Bits [1:0]: Internal Data format:
  [7:4] AXC_INDEX0_LUT rw — Even Addresses: Bits [3:0]: antenna carrier index, 0-15 used for address generation for circuit switched types (unused for packet switched types)
  [3:2] PKT_FIFO_INDEX0_LUT rw — Even Addresses: Bits [1:0]: Fifo index (used for packet switched type), 0-3 used to direct message to one of four FIFOs.
    0=PS_FIFO0; 1=PS_FIFO1; 2=PS_FIFO2; 3=ERR_FIFO
  [1] AXC_CAPT_EN0_LUT rw — Even Addresses: 1'b1 causes circuit switched type to also capture to Error FIFO (fifo index 0x3)
  [0] BAD_ADR0_LUT rw — Even Addresses: Illegal Address 1'b1: address is indicated to be illegal. Error condition is triggered.
{0x28000+0x800*i} PE_LINK_84_EN_LUT0_CFG{i} rw (i=0..5) — Protocol Encoder 84 Count Message Enable bits
  [31:0] MSG_SLOT_84_EN_LUT0 — Bits [31:0], Bit mapped by 84 count. Enable of a particular message slot.
{0x28004+0x800*i} PE_LINK_84_EN_LUT1_CFG{i} rw (i=0..5) — Protocol Encoder 84 Count Message Enable bits
  [31:0] MSG_SLOT_84_EN_LUT1 — Bits [63:32], Bit mapped by 84 count. Enable of a particular message slot.
{0x28008+0x800*i} PE_LINK_84_EN_LUT2_CFG{i} (i=0..5) — Protocol Encoder 84 Count Message Enable bits
  [19:0] MSG_SLOT_84_EN_LUT2 rw — Bits [83:64], Bit mapped by 84 count. Enable of a particular message slot.
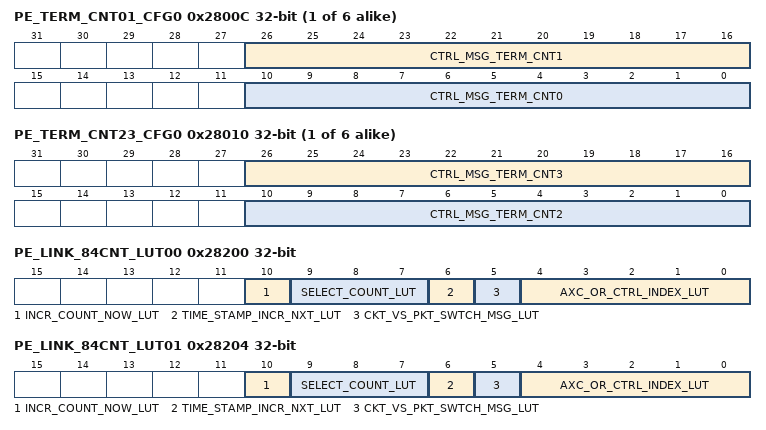
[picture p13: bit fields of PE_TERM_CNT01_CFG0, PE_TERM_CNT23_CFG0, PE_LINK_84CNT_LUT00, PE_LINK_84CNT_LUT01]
{0x2800C+0x800*i} PE_TERM_CNT01_CFG{i} (i=0..5) — Protocol Encoder Terminal Count 0 and 1
  [26:16] CTRL_MSG_TERM_CNT1 rw — Sets terminal count for control message
  [10:0] CTRL_MSG_TERM_CNT0 rw — Sets terminal count for control message
{0x28010+0x800*i} PE_TERM_CNT23_CFG{i} (i=0..5) — Protocol Encoder Terminal Count 0 and 1
  [26:16] CTRL_MSG_TERM_CNT3 rw — Sets terminal count for control message
  [10:0] CTRL_MSG_TERM_CNT2 rw — Sets terminal count for control message
0x28200 PE_LINK_84CNT_LUT00 — Protocol Encoder Link 84 Count LUT{PE_LINK_84CNT_LUT0}
  [10] INCR_COUNT_NOW_LUT rw — controls counter to increment, Incremented value is used for next operation (current operation uses current counter value)
    1=ICNR; 0=NO_INCR
  [9:7] SELECT_COUNT_LUT rw — Bits [2:0]: "0"-"3": Selects 4x Control Slot Counters or "4": 1x Data Slot Counter for Increment and for use with transmission rule
    {v}=CTRL{v} (v=0..3); 4=DATA
  [6] TIME_STAMP_INCR_NXT_LUT rw — Controls Time Stamp to increment, Incremented value is used for next message
  [5] CKT_VS_PKT_SWTCH_MSG_LUT rw — 0: circuit switched data
    0=PACKET; 1=CIRCUIT
  [4:0] AXC_OR_CTRL_INDEX_LUT rw — Bits [4:0]: Index for accessing the identity LUT.
0x28204 PE_LINK_84CNT_LUT01 — Protocol Encoder Link 84 Count LUT{PE_LINK_84CNT_LUT0}
  fields as PE_LINK_84CNT_LUT00
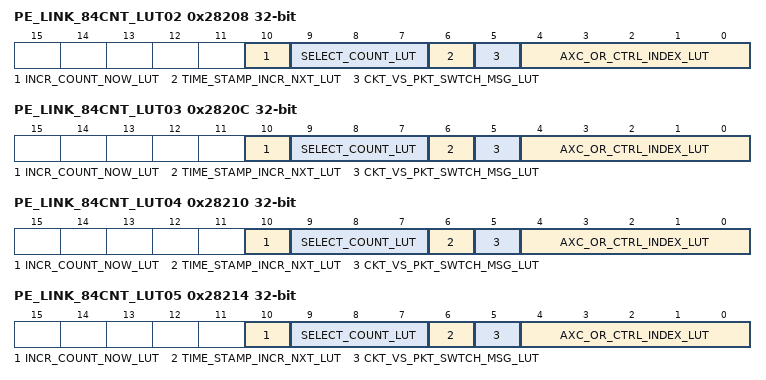
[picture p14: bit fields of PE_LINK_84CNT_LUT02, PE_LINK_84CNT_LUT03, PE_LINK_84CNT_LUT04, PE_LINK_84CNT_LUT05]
0x28208 PE_LINK_84CNT_LUT02 — Protocol Encoder Link 84 Count LUT{PE_LINK_84CNT_LUT0}
  fields as PE_LINK_84CNT_LUT00
0x2820C PE_LINK_84CNT_LUT03 — Protocol Encoder Link 84 Count LUT{PE_LINK_84CNT_LUT0}
  fields as PE_LINK_84CNT_LUT00
0x28210 PE_LINK_84CNT_LUT04 — Protocol Encoder Link 84 Count LUT{PE_LINK_84CNT_LUT0}
  fields as PE_LINK_84CNT_LUT00
0x28214 PE_LINK_84CNT_LUT05 — Protocol Encoder Link 84 Count LUT{PE_LINK_84CNT_LUT0}
  fields as PE_LINK_84CNT_LUT00
0x28218 PE_LINK_84CNT_LUT06 — Protocol Encoder Link 84 Count LUT{PE_LINK_84CNT_LUT0}
  fields as PE_LINK_84CNT_LUT00
0x2821C PE_LINK_84CNT_LUT07 — Protocol Encoder Link 84 Count LUT{PE_LINK_84CNT_LUT0}
  fields as PE_LINK_84CNT_LUT00
0x28220 PE_LINK_84CNT_LUT08 — Protocol Encoder Link 84 Count LUT{PE_LINK_84CNT_LUT0}
  fields as PE_LINK_84CNT_LUT00
0x28224 PE_LINK_84CNT_LUT09 — Protocol Encoder Link 84 Count LUT{PE_LINK_84CNT_LUT0}
  fields as PE_LINK_84CNT_LUT00
0x28228 PE_LINK_84CNT_LUT010 — Protocol Encoder Link 84 Count LUT{PE_LINK_84CNT_LUT0}
  fields as PE_LINK_84CNT_LUT00
0x2822C PE_LINK_84CNT_LUT011 — Protocol Encoder Link 84 Count LUT{PE_LINK_84CNT_LUT0}
  fields as PE_LINK_84CNT_LUT00
0x28230 PE_LINK_84CNT_LUT012 — Protocol Encoder Link 84 Count LUT{PE_LINK_84CNT_LUT0}
  fields as PE_LINK_84CNT_LUT00
0x28234 PE_LINK_84CNT_LUT013 — Protocol Encoder Link 84 Count LUT{PE_LINK_84CNT_LUT0}
  fields as PE_LINK_84CNT_LUT00
0x28238 PE_LINK_84CNT_LUT014 — Protocol Encoder Link 84 Count LUT{PE_LINK_84CNT_LUT0}
  fields as PE_LINK_84CNT_LUT00
0x2823C PE_LINK_84CNT_LUT015 — Protocol Encoder Link 84 Count LUT{PE_LINK_84CNT_LUT0}
  fields as PE_LINK_84CNT_LUT00
0x28240 PE_LINK_84CNT_LUT016 — Protocol Encoder Link 84 Count LUT{PE_LINK_84CNT_LUT0}
  fields as PE_LINK_84CNT_LUT00
0x28244 PE_LINK_84CNT_LUT017 — Protocol Encoder Link 84 Count LUT{PE_LINK_84CNT_LUT0}
  fields as PE_LINK_84CNT_LUT00
0x28248 PE_LINK_84CNT_LUT018 — Protocol Encoder Link 84 Count LUT{PE_LINK_84CNT_LUT0}
  fields as PE_LINK_84CNT_LUT00
0x2824C PE_LINK_84CNT_LUT019 — Protocol Encoder Link 84 Count LUT{PE_LINK_84CNT_LUT0}
  fields as PE_LINK_84CNT_LUT00
0x28250 PE_LINK_84CNT_LUT020 — Protocol Encoder Link 84 Count LUT{PE_LINK_84CNT_LUT0}
  fields as PE_LINK_84CNT_LUT00
0x28254 PE_LINK_84CNT_LUT021 — Protocol Encoder Link 84 Count LUT{PE_LINK_84CNT_LUT0}
  fields as PE_LINK_84CNT_LUT00
0x28258 PE_LINK_84CNT_LUT022 — Protocol Encoder Link 84 Count LUT{PE_LINK_84CNT_LUT0}
  fields as PE_LINK_84CNT_LUT00
0x2825C PE_LINK_84CNT_LUT023 — Protocol Encoder Link 84 Count LUT{PE_LINK_84CNT_LUT0}
  fields as PE_LINK_84CNT_LUT00
0x28260 PE_LINK_84CNT_LUT024 — Protocol Encoder Link 84 Count LUT{PE_LINK_84CNT_LUT0}
  fields as PE_LINK_84CNT_LUT00
0x28264 PE_LINK_84CNT_LUT025 — Protocol Encoder Link 84 Count LUT{PE_LINK_84CNT_LUT0}
  fields as PE_LINK_84CNT_LUT00
0x28268 PE_LINK_84CNT_LUT026 — Protocol Encoder Link 84 Count LUT{PE_LINK_84CNT_LUT0}
  fields as PE_LINK_84CNT_LUT00
0x2826C PE_LINK_84CNT_LUT027 — Protocol Encoder Link 84 Count LUT{PE_LINK_84CNT_LUT0}
  fields as PE_LINK_84CNT_LUT00
0x28270 PE_LINK_84CNT_LUT028 — Protocol Encoder Link 84 Count LUT{PE_LINK_84CNT_LUT0}
  fields as PE_LINK_84CNT_LUT00
0x28274 PE_LINK_84CNT_LUT029 — Protocol Encoder Link 84 Count LUT{PE_LINK_84CNT_LUT0}
  fields as PE_LINK_84CNT_LUT00
0x28278 PE_LINK_84CNT_LUT030 — Protocol Encoder Link 84 Count LUT{PE_LINK_84CNT_LUT0}
  fields as PE_LINK_84CNT_LUT00
0x2827C PE_LINK_84CNT_LUT031 — Protocol Encoder Link 84 Count LUT{PE_LINK_84CNT_LUT0}
  fields as PE_LINK_84CNT_LUT00
0x28280 PE_LINK_84CNT_LUT032 — Protocol Encoder Link 84 Count LUT{PE_LINK_84CNT_LUT0}
  fields as PE_LINK_84CNT_LUT00
0x28284 PE_LINK_84CNT_LUT033 — Protocol Encoder Link 84 Count LUT{PE_LINK_84CNT_LUT0}
  fields as PE_LINK_84CNT_LUT00
0x28288 PE_LINK_84CNT_LUT034 — Protocol Encoder Link 84 Count LUT{PE_LINK_84CNT_LUT0}
  fields as PE_LINK_84CNT_LUT00
0x2828C PE_LINK_84CNT_LUT035 — Protocol Encoder Link 84 Count LUT{PE_LINK_84CNT_LUT0}
  fields as PE_LINK_84CNT_LUT00
0x28290 PE_LINK_84CNT_LUT036 — Protocol Encoder Link 84 Count LUT{PE_LINK_84CNT_LUT0}
  fields as PE_LINK_84CNT_LUT00
0x28294 PE_LINK_84CNT_LUT037 — Protocol Encoder Link 84 Count LUT{PE_LINK_84CNT_LUT0}
  fields as PE_LINK_84CNT_LUT00
0x28298 PE_LINK_84CNT_LUT038 — Protocol Encoder Link 84 Count LUT{PE_LINK_84CNT_LUT0}
  fields as PE_LINK_84CNT_LUT00
0x2829C PE_LINK_84CNT_LUT039 — Protocol Encoder Link 84 Count LUT{PE_LINK_84CNT_LUT0}
  fields as PE_LINK_84CNT_LUT00
0x282A0 PE_LINK_84CNT_LUT040 — Protocol Encoder Link 84 Count LUT{PE_LINK_84CNT_LUT0}
  fields as PE_LINK_84CNT_LUT00
0x282A4 PE_LINK_84CNT_LUT041 — Protocol Encoder Link 84 Count LUT{PE_LINK_84CNT_LUT0}
  fields as PE_LINK_84CNT_LUT00
0x282A8 PE_LINK_84CNT_LUT042 — Protocol Encoder Link 84 Count LUT{PE_LINK_84CNT_LUT0}
  fields as PE_LINK_84CNT_LUT00
0x282AC PE_LINK_84CNT_LUT043 — Protocol Encoder Link 84 Count LUT{PE_LINK_84CNT_LUT0}
  fields as PE_LINK_84CNT_LUT00
0x282B0 PE_LINK_84CNT_LUT044 — Protocol Encoder Link 84 Count LUT{PE_LINK_84CNT_LUT0}
  fields as PE_LINK_84CNT_LUT00
0x282B4 PE_LINK_84CNT_LUT045 — Protocol Encoder Link 84 Count LUT{PE_LINK_84CNT_LUT0}
  fields as PE_LINK_84CNT_LUT00
0x282B8 PE_LINK_84CNT_LUT046 — Protocol Encoder Link 84 Count LUT{PE_LINK_84CNT_LUT0}
  fields as PE_LINK_84CNT_LUT00
0x282BC PE_LINK_84CNT_LUT047 — Protocol Encoder Link 84 Count LUT{PE_LINK_84CNT_LUT0}
  fields as PE_LINK_84CNT_LUT00
